# M2Sxxx register map
Vendor: Microsemi; Series: SmartFusion2; File version: 2.0.32
CPU: CM3 r2p1, little endian, MPU, no FPU, 4 interrupt priority bits
Registers are 32-bit, read-write, no defined reset value unless marked. A register's access mark holds for its fields unless they carry their own. Offsets are from the block's base; [hi:lo] are bit positions.

## RTC — No description provided for this peripheral
Base 0x40017000
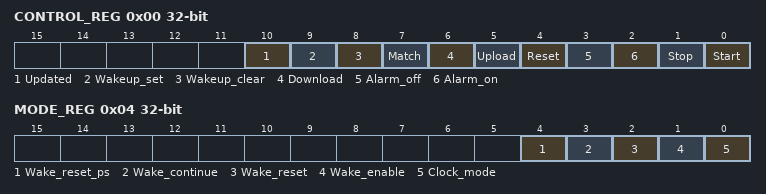
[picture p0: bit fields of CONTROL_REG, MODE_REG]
0x00 CONTROL_REG — No description provided for this register
  [10] Updated — No description provided for this field
  [9] Wakeup_set — No description provided for this field
  [8] Wakeup_clear — No description provided for this field
  [7] Match — No description provided for this field
  [6] Download — No description provided for this field
  [5] Upload — No description provided for this field
  [4] Reset — No description provided for this field
  [3] Alarm_off — No description provided for this field
  [2] Alarm_on — No description provided for this field
  [1] Stop — No description provided for this field
  [0] Start — No description provided for this field
0x04 MODE_REG — No description provided for this register
  [4] Wake_reset_ps — No description provided for this field
  [3] Wake_continue — No description provided for this field
  [2] Wake_reset — No description provided for this field
  [1] Wake_enable — No description provided for this field
  [0] Clock_mode — No description provided for this field
0x08 PRESCALER_REG — No description provided for this register
  [25:0] Prescaler — No description provided for this field
0x0C ALARM_LOWER_REG — No description provided for this register
  [31:0] Alarm_lower — No description provided for this field
0x10 ALARM_UPPER_REG — No description provided for this register
  [31:0] Alarm_upper — No description provided for this field
0x14 COMPARE_LOWER_REG — No description provided for this register
  [31:0] Compare_lower — No description provided for this field
0x18 COMPARE_UPPER_REG — No description provided for this register
  [31:0] Compare_upper — No description provided for this field
0x20 DATE_TIME_LOWER_REG — No description provided for this register
  [31:0] Datetime_Lower — No description provided for this field
0x24 DATE_TIME_UPPER_REG — No description provided for this register
  [31:0] Datetime_Upper — No description provided for this field
0x30 SECONDS_REG — No description provided for this register
  [5:0] Seconds — No description provided for this field
0x34 MINUTES_REG — No description provided for this register
  [5:0] Minutes — No description provided for this field
0x38 HOURS_REG — No description provided for this register
  [4:0] Hours — No description provided for this field
0x3C DAY_REG — No description provided for this register
  [4:0] Day — No description provided for this field
0x40 MONTH_REG — No description provided for this register
  [4:0] Month — No description provided for this field
0x44 YEAR_REG — No description provided for this register
  [7:0] Year — No description provided for this field
0x48 WEEKDAY_REG — No description provided for this register
  [2:0] Weekday — No description provided for this field
0x4C WEEK_REG — No description provided for this register
  [5:0] Week — No description provided for this field
0x50 SECONDS_CNT_REG — No description provided for this register
  [5:0] Seconds — No description provided for this field
0x54 MINUTES_CNT_REG — No description provided for this register
  [5:0] Minutes — No description provided for this field
0x58 HOURS_CNT_REG — No description provided for this register
  [4:0] Hours — No description provided for this field
0x5C DAY_CNT_REG — No description provided for this register
  [4:0] Day — No description provided for this field
0x60 MONTH_CNT_REG — No description provided for this register
  [4:0] Month — No description provided for this field
0x64 YEAR_CNT_REG — No description provided for this register
  [7:0] Year — No description provided for this field
0x68 WEEKDAY_CNT_REG — No description provided for this register
  [2:0] Weekday — No description provided for this field
0x6C WEEK_CNT_REG — No description provided for this register
  [5:0] Week — No description provided for this field
